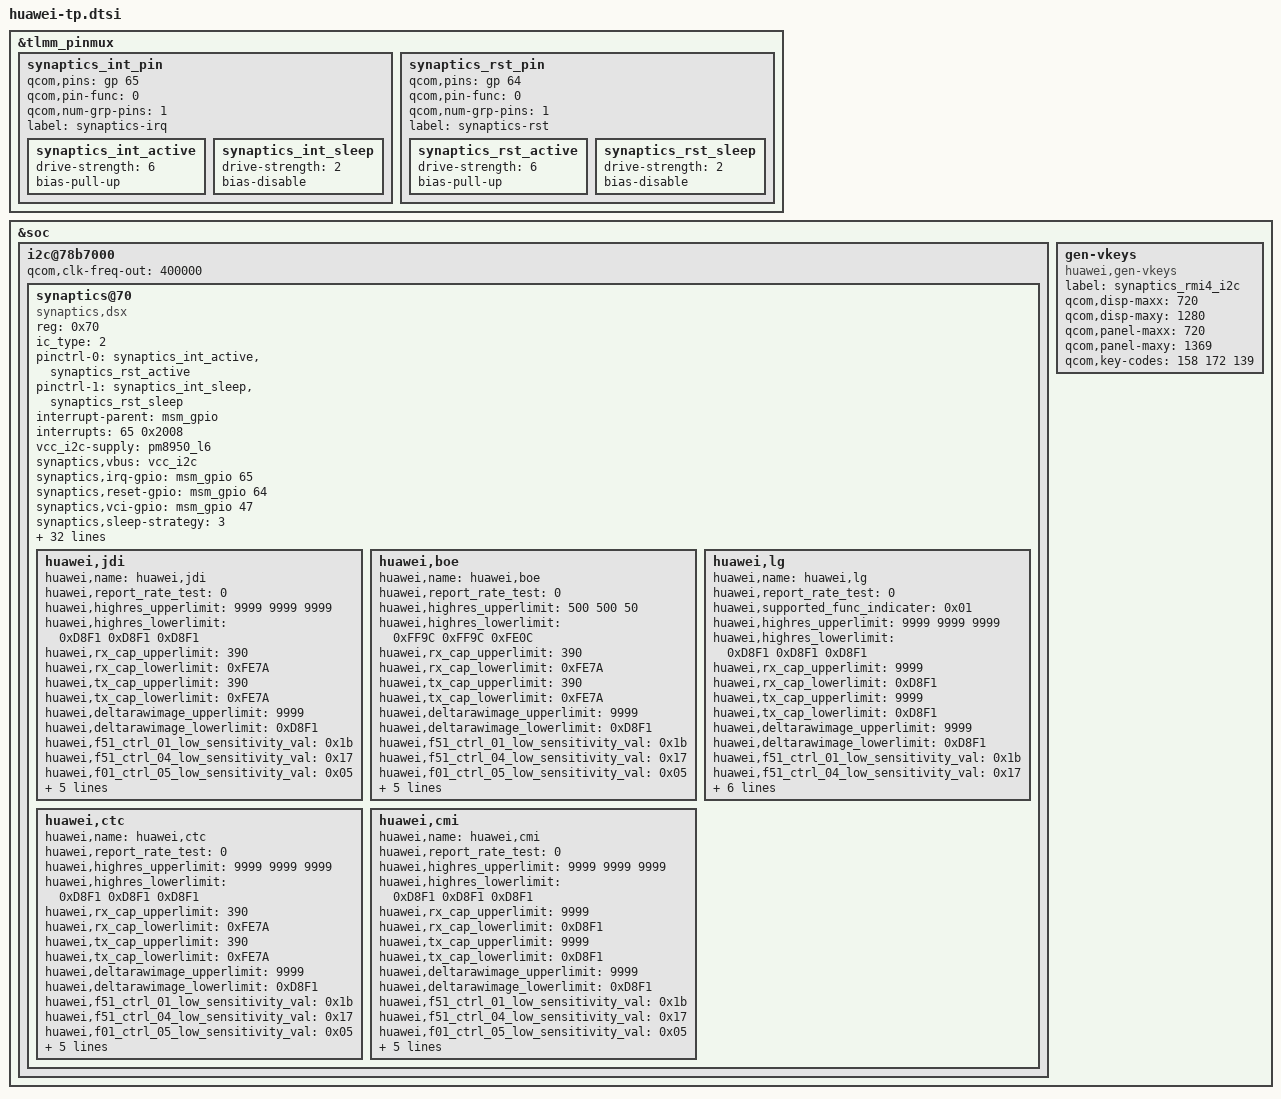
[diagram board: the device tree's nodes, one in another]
/* Modify JDI tp/lcd power on/off to reduce power consumption */
/* Modify JDI tp reset gpio pinctrl for power consumption */
/*Ath TP not working in glove mode*/
/* move l16 control to ATH device config file */
&tlmm_pinmux {

	synaptics_int_pin {
		qcom,pins = <&gp 65>;
		qcom,pin-func = <0>;
		qcom,num-grp-pins = <1>;
		label = "synaptics-irq";
		synaptics_int_active: synaptics_int_active {
			drive-strength = <6>;
			bias-pull-up;
		};
		synaptics_int_sleep: synaptics_int_sleep {
			drive-strength = <2>;
			bias-disable;
		};
	};

	synaptics_rst_pin {
		qcom,pins = <&gp 64>;
		qcom,pin-func = <0>;
		qcom,num-grp-pins = <1>;
		label = "synaptics-rst";
		synaptics_rst_active: synaptics_rst_active {
			drive-strength = <6>;
			bias-pull-up;
		};
		synaptics_rst_sleep: synaptics_rst_sleep {
			drive-strength = <2>;
			bias-disable;
		};
	};
};

&soc {
    i2c@78b7000 { /* BLSP1 QUP5 */
		status = "ok";
		#address-cells = <1>;
		#size-cells = <0>;
		qcom,clk-freq-out = <400000>;
		synaptics@70 {
			compatible = "synaptics,dsx";
			reg = <0x70>;

			/* SYNAPTICS_S3207 = 0 */
			/* SYNAPTICS_S3350 = 1 */
			/* SYNAPTICS_S3320 = 2 */
			/* SYNAPTICS_S3718 = 3 */
			ic_type = <2>;

			pinctrl-names = "active","sleep";
			pinctrl-0 = <&synaptics_int_active &synaptics_rst_active>;
			pinctrl-1 = <&synaptics_int_sleep &synaptics_rst_sleep>;

			interrupt-parent = <&msm_gpio>;
			interrupts = <65 0x2008>;
			//vdd-supply = <&pm8950_l17>;
			vcc_i2c-supply = <&pm8950_l6>;
			/* Some of qcom's param will not be replaced by huawei in dtb, */
			/* just ignore them:such as "pinctrl-names","pinctrl-0","pinctrl-1", */
			/* "synaptics,display-coords","synaptics,panel-coords","synaptics,i2c-pull-up", */
			/* "synaptics,power-down","synaptics,disable-gpios"*/
			//synaptics,vdd = "vdd";
			synaptics,vbus = "vcc_i2c";
			synaptics,irq-gpio = <&msm_gpio 65 0x2008>;
			synaptics,reset-gpio = <&msm_gpio 64 0x0>;
			synaptics,vci-gpio = <&msm_gpio 47 0x0>;

			/* synaptics,sleep/wake strategy */

			/* SLEEP_STRATEGY_DEEP_SLEEP    : 0*/
			/* SLEEP_STRATEGY_POWER_DOWN    : 1*/
			/* SLEEP_STRATEGY_KEEP_WAKE     : 2*/
			/* SLEEP_STRATEGY_ALWAYS_RESET  : 3*/
			synaptics,sleep-strategy = <3>;

			synaptics,lcd-x = <1080>;
			synaptics,lcd-y = <1920>;
			synaptics,lcd-all = <1920>;
			synaptics,virtual_keys = /* KeyCode CenterX CenterY Width Height */
				/* KEY_BACK */
				<158 142 1342 150 100
				/* KEY_HOME(172) */
				172 360 1342 150 100
				/* KEY_MENU */
				139 578 1342 150 100>;

			/* SYNAPTICS_WAKE_UP_GESTURE_FLAG:'1'->enabled,'0'->disabled */
			/*IC flash is not enough for holster,so fw del one gesture*/
			synaptics,gesture_enabled = <0>;
			/* Gestures that supported:                           */
			/* bit0  Double tap                                        */
			/* bit1  Single finger slide from left to right     */
			/* bit2  Single finger slide from right to left     */
			/* bit3  Single finger slide from top to bottom  */
			/* bit4  Single finger slide from bottom to top  */
			/* bit5  Double finger slide from top to bottom--disable for holster*/
			/* bit6  Single finger slide circle                     */
			/* bit7  Single finger write letter c                  */
			/* bit8  Single finger write letter e                  */
			/* bit9  Single finger write letter m                 */
			/* bit10 Single finger write letter w                 */
			/* bit11 Palm off screen                                */
			synaptics,easy_wakeup_supported_gestures = <0xF81>;

			/*Defination of report key value  for different gestures*/
			synaptics,easy_wakeup_gesture_keys = 
			<	59 /*0.Double tap:                                  KEY_F1*/
				60 /*1.Single finger slide from left to right:      KEY_F2*/
				61 /*2.Single finger slide from right to left:      KEY_F3*/
				62 /*3.Single finger slide from top to bottom:      KEY_F4*/
				63 /*4.Single finger slide from bottom to top:      KEY_F5*/
				64 /*5.Single finger slide circle clockwise:        KEY_F6*/
				65 /*6.Single finger slide circle counter-clockwise:KEY_F7*/
				66 /*7.Single finger write letter c:                KEY_F8*/
				67 /*8.Single finger write letter e:                KEY_F9*/
				68 /*9.Single finger write letter m:                KEY_F10*/
				87 /*10.Single finger write letter w:               KEY_F11*/
				88 /*11.Palm off screen:                            KEY_F12*/
			>;

			/* Double-tap-zone defined by huawei */
			/* Shielded area is:1cm left,1cm right,3cm up,2cm down */
			huawei,dtz_x0 = <1>;
			huawei,dtz_y0 = <1>;
			huawei,dtz_x1 = <1080>;
			huawei,dtz_y1 = <1920>;

			/* GLOVE FLAG default state:'1'->enabled,'0'->disabled*/
			synaptics,glove_enabled = <0>;
			/*After reduce power-consumption by exit reduce mode,*/
			/*we have to reduce f-r rate to make sure gesture work fine*/
			synaptics,fast_relax_gesture = <0>;
			/*Holster support flag*/
			synaptics,holster_supported = <0>;
			synaptics,glove_edge_switch_supported = <0>;
			synaptics,grip_algorithm_supported = <0>;
			synaptics,grip_algorithm_enabled = <0>;
			huawei,grip_left_lsb = <0x32>;
			huawei,grip_left_msb = <0x0>;
			huawei,grip_right_lsb = <0x1A>;
			huawei,grip_right_msb = <0x04>;

			/*dwt represent doze wakeup threshold in gesture mode*/
			synaptics,ofilm_dwt = <30>;
			synaptics,truly_dwt = <30>;
			synaptics,junda_dwt = <30>;

			synaptics,reset-on-status = <0>;
			synaptics,power-delay-ms = <160>;
			synaptics,reset-delay-ms = <200>;
			synaptics,reset-active-ms = <10>;
			synaptics,product_name = "venus";

			/*capacitance self-adapt*/
			huawei,jdi {
				huawei,name = "huawei,jdi";
				huawei,report_rate_test = <0>; /* 0:disable test, 1:enable test */

				huawei,highres_upperlimit = <9999 9999 9999>;
				huawei,highres_lowerlimit = <0xD8F1 0xD8F1 0xD8F1>;/* 0xD8F1 == -9999 */

				huawei,rx_cap_upperlimit = <390>;
				huawei,rx_cap_lowerlimit = <0xFE7A>;

				huawei,tx_cap_upperlimit = <390>;
				huawei,tx_cap_lowerlimit = <0xFE7A>;

				huawei,deltarawimage_upperlimit = <9999>;
				huawei,deltarawimage_lowerlimit = <0xD8F1>;

				huawei,f51_ctrl_01_low_sensitivity_val = <0x1b>;
				huawei,f51_ctrl_04_low_sensitivity_val = <0x17>;
				huawei,f01_ctrl_05_low_sensitivity_val = <0x05>;
				huawei,f01_ctrl_09_low_sensitivity_val = <0x04>;

				huawei,fullraw_upperlimit =
					<2550 2550 2550 2550 2550 2550 2550 2550 2550 2550 2550 2550 2550 2550 2550 2550
					2550 2550 2550 2550 2550 2550 2550 2550 2550 2550 2550 2550 2550 2550 2550 2550
					2550 2550 2550 2550 2550 2550 2550 2550 2550 2550 2550 2550 2550 2550 2550 2550
					2550 2550 2550 2550 2550 2550 2550 2550 2550 2550 2550 2550 2550 2550 2550 2550
					2550 2550 2550 2550 2550 2550 2550 2550 2550 2550 2550 2550 2550 2550 2550 2550
					2550 2550 2550 2550 2550 2550 2550 2550 2550 2550 2550 2550 2550 2550 2550 2550
					2550 2550 2550 2550 2550 2550 2550 2550 2550 2550 2550 2550 2550 2550 2550 2550
					2550 2550 2550 2550 2550 2550 2550 2550 2550 2550 2550 2550 2550 2550 2550 2550
					2550 2550 2550 2550 2550 2550 2550 2550 2550 2550 2550 2550 2550 2550 2550 2550
					2550 2550 2550 2550 2550 2550 2550 2550 2550 2550 2550 2550 2550 2550 2550 2550
					2550 2550 2550 2550 2550 2550 2550 2550 2550 2550 2550 2550 2550 2550 2550 2550
					2550 2550 2550 2550 2550 2550 2550 2550 2550 2550 2550 2550 2550 2550 2550 2550
					2550 2550 2550 2550 2550 2550 2550 2550 2550 2550 2550 2550 2550 2550 2550 2550
					2550 2550 2550 2550 2550 2550 2550 2550 2550 2550 2550 2550 2550 2550 2550 2550
					2550 2550 2550 2550 2550 2550 2550 2550 2550 2550 2550 2550 2550 2550 2550 2550
					2550 2550 2550 2550 2550 2550 2550 2550 2550 2550 2550 2550 2550 2550 2550 2550
					2550 2550 2550 2550 2550 2550 2550 2550 2550 2550 2550 2550 2550 2550 2550 2550
					2550 2550 2550 2550 2550 2550 2550 2550 2550 2550 2550 2550 2550 2550 2550 2550
					2550 2550 2550 2550 2550 2550 2550 2550 2550 2550 2550 2550 2550 2550 2550 2550
					2550 2550 2550 2550 2550 2550 2550 2550 2550 2550 2550 2550 2550 2550 2550 2550
					2550 2550 2550 2550 2550 2550 2550 2550 2550 2550 2550 2550 2550 2550 2550 2550
					2550 2550 2550 2550 2550 2550 2550 2550 2550 2550 2550 2550 2550 2550 2550 2550
					2550 2550 2550 2550 2550 2550 2550 2550 2550 2550 2550 2550 2550 2550 2550 2550
					2550 2550 2550 2550 2550 2550 2550 2550 2550 2550 2550 2550 2550 2550 2550 2550
					2550 2550 2550 2550 2550 2550 2550 2550 2550 2550 2550 2550 2550 2550 2550 2550
					2550 2550 2550 2550 2550 2550 2550 2550 2550 2550 2550 2550 2550 2550 2550 2550
					2550 2550 2550 2550 2550 2550 2550 2550 2550 2550 2550 2550 2550 2550 2550 2550
					2550 2550 2550 2550 2550 2550 2550 2550 2550 2550 2550 2550 2550 2550 2550 2550>;

				huawei,fullraw_lowerlimit =
					<1500 1500 1500 1500 1500 1500 1500 1500 1500 1500 1500 1500 1500 1500 1500 1500
					1500 1500 1500 1500 1500 1500 1500 1500 1500 1500 1500 1500 1500 1500 1500 1500
					1500 1500 1500 1500 1500 1500 1500 1500 1500 1500 1500 1500 1500 1500 1500 1500
					1500 1500 1500 1500 1500 1500 1500 1500 1500 1500 1500 1500 1500 1500 1500 1500
					1500 1500 1500 1500 1500 1500 1500 1500 1500 1500 1500 1500 1500 1500 1500 1500
					1500 1500 1500 1500 1500 1500 1500 1500 1500 1500 1500 1500 1500 1500 1500 1500
					1500 1500 1500 1500 1500 1500 1500 1500 1500 1500 1500 1500 1500 1500 1500 1500
					1500 1500 1500 1500 1500 1500 1500 1500 1500 1500 1500 1500 1500 1500 1500 1500
					1500 1500 1500 1500 1500 1500 1500 1500 1500 1500 1500 1500 1500 1500 1500 1500
					1500 1500 1500 1500 1500 1500 1500 1500 1500 1500 1500 1500 1500 1500 1500 1500
					1500 1500 1500 1500 1500 1500 1500 1500 1500 1500 1500 1500 1500 1500 1500 1500
					1500 1500 1500 1500 1500 1500 1500 1500 1500 1500 1500 1500 1500 1500 1500 1500
					1500 1500 1500 1500 1500 1500 1500 1500 1500 1500 1500 1500 1500 1500 1500 1500
					1500 1500 1500 1500 1500 1500 1500 1500 1500 1500 1500 1500 1500 1500 1500 1500
					1500 1500 1500 1500 1500 1500 1500 1500 1500 1500 1500 1500 1500 1500 1500 1500
					1500 1500 1500 1500 1500 1500 1500 1500 1500 1500 1500 1500 1500 1500 1500 1500
					1500 1500 1500 1500 1500 1500 1500 1500 1500 1500 1500 1500 1500 1500 1500 1500
					1500 1500 1500 1500 1500 1500 1500 1500 1500 1500 1500 1500 1500 1500 1500 1500
					1500 1500 1500 1500 1500 1500 1500 1500 1500 1500 1500 1500 1500 1500 1500 1500
					1500 1500 1500 1500 1500 1500 1500 1500 1500 1500 1500 1500 1500 1500 1500 1500
					1500 1500 1500 1500 1500 1500 1500 1500 1500 1500 1500 1500 1500 1500 1500 1500
					1500 1500 1500 1500 1500 1500 1500 1500 1500 1500 1500 1500 1500 1500 1500 1500
					1500 1500 1500 1500 1500 1500 1500 1500 1500 1500 1500 1500 1500 1500 1500 1500
					1500 1500 1500 1500 1500 1500 1500 1500 1500 1500 1500 1500 1500 1500 1500 1500
					1500 1500 1500 1500 1500 1500 1500 1500 1500 1500 1500 1500 1500 1500 1500 1500
					1500 1500 1500 1500 1500 1500 1500 1500 1500 1500 1500 1500 1500 1500 1500 1500
					1500 1500 1500 1500 1500 1500 1500 1500 1500 1500 1500 1500 1500 1500 1500 1500
					1500 1500 1500 1500 1500 1500 1500 1500 1500 1500 1500 1500 1500 1500 1500 1500>;
			};

			huawei,boe {
				huawei,name = "huawei,boe";
				huawei,report_rate_test = <0>; /* 0:disable test, 1:enable test */

				huawei,highres_upperlimit = <500 500 50>;
				huawei,highres_lowerlimit = <0xFF9C 0xFF9C 0xFE0C>;/* 0xD8F1 == -9999 */

				huawei,rx_cap_upperlimit = <390>;
				huawei,rx_cap_lowerlimit = <0xFE7A>;

				huawei,tx_cap_upperlimit = <390>;
				huawei,tx_cap_lowerlimit = <0xFE7A>;

				huawei,deltarawimage_upperlimit = <9999>;
				huawei,deltarawimage_lowerlimit = <0xD8F1>;

				huawei,f51_ctrl_01_low_sensitivity_val = <0x1b>;
				huawei,f51_ctrl_04_low_sensitivity_val = <0x17>;
				huawei,f01_ctrl_05_low_sensitivity_val = <0x05>;
				huawei,f01_ctrl_09_low_sensitivity_val = <0x04>;

				huawei,fullraw_upperlimit =
					<3394 3354 3291 3253 3117 3109 3105 3103 3089 3100 3092 3104 3243 3288 3358 3434
					3534 3515 3455 3416 3276 3269 3264 3263 3250 3261 3254 3267 3405 3450 3519 3560
					3557 3543 3482 3444 3304 3296 3292 3290 3277 3289 3283 3295 3433 3478 3547 3583
					3573 3561 3502 3465 3325 3318 3313 3311 3299 3310 3304 3315 3454 3497 3566 3599
					3588 3579 3520 3485 3345 3337 3333 3331 3319 3331 3324 3336 3474 3516 3582 3614
					3596 3589 3531 3496 3357 3349 3344 3343 3330 3341 3335 3346 3484 3526 3591 3622
					3605 3598 3541 3506 3368 3360 3356 3353 3340 3352 3345 3356 3494 3535 3600 3630
					3609 3603 3546 3511 3372 3365 3366 3357 3344 3355 3349 3360 3497 3539 3604 3633
					3613 3606 3550 3515 3376 3369 3364 3362 3349 3359 3353 3364 3502 3544 3608 3637
					3611 3605 3549 3514 3374 3367 3363 3360 3347 3358 3352 3363 3501 3542 3606 3635
					3613 3607 3550 3516 3376 3368 3364 3361 3348 3358 3353 3364 3501 3543 3607 3636
					3610 3603 3546 3512 3372 3364 3359 3358 3346 3356 3350 3361 3498 3538 3603 3631
					3610 3603 3546 3512 3373 3365 3361 3358 3346 3356 3350 3361 3496 3538 3602 3631
					3605 3598 3541 3507 3367 3361 3356 3353 3341 3351 3346 3356 3492 3533 3597 3626
					3599 3591 3534 3501 3361 3354 3350 3347 3335 3346 3341 3350 3486 3526 3590 3619
					3586 3579 3523 3490 3350 3343 3338 3336 3324 3335 3329 3338 3475 3515 3578 3609
					3577 3569 3513 3480 3341 3334 3329 3329 3317 3327 3321 3330 3465 3506 3568 3598
					3563 3555 3499 3466 3328 3321 3317 3317 3304 3315 3308 3316 3452 3492 3554 3583
					3547 3538 3483 3449 3310 3304 3300 3300 3288 3298 3291 3300 3435 3474 3536 3567
					3538 3530 3474 3441 3302 3296 3292 3292 3279 3289 3283 3292 3427 3466 3528 3557
					3524 3517 3460 3427 3289 3283 3278 3278 3265 3276 3269 3279 3413 3453 3514 3544
					3510 3501 3446 3413 3274 3267 3262 3262 3250 3260 3253 3263 3398 3437 3499 3529
					3497 3489 3432 3399 3263 3254 3250 3249 3238 3247 3239 3249 3384 3423 3485 3515
					3481 3473 3415 3382 3243 3238 3235 3234 3223 3231 3223 3232 3367 3407 3469 3498
					3469 3460 3403 3369 3230 3225 3221 3222 3210 3219 3210 3218 3353 3393 3457 3488
					3454 3444 3385 3351 3212 3207 3205 3205 3194 3204 3193 3201 3336 3378 3441 3475
					3439 3426 3369 3334 3195 3189 3187 3189 3178 3187 3176 3184 3320 3362 3425 3461
					3331 3303 3244 3208 3071 3062 3063 3062 3051 3065 3054 3062 3201 3242 3305 3356>;

				huawei,fullraw_lowerlimit =
					<1779 1754 1719 1708 1644 1646 1646 1636 1634 1631 1634 1635 1708 1728 1767 1800
					1848 1835 1801 1789 1724 1724 1725 1714 1714 1710 1715 1716 1792 1809 1850 1869
					1857 1845 1810 1797 1733 1734 1735 1724 1725 1722 1726 1733 1803 1821 1860 1878
					1867 1854 1818 1806 1741 1742 1744 1733 1735 1732 1736 1740 1813 1830 1870 1889
					1876 1864 1828 1817 1750 1751 1751 1742 1744 1741 1744 1745 1821 1839 1880 1897
					1881 1868 1833 1824 1757 1757 1757 1747 1751 1747 1750 1750 1826 1845 1887 1903
					1887 1873 1838 1831 1764 1763 1764 1755 1758 1755 1757 1758 1834 1853 1894 1910
					1885 1872 1838 1828 1762 1761 1764 1755 1758 1755 1758 1760 1835 1854 1896 1913
					1885 1872 1838 1828 1761 1762 1763 1751 1756 1754 1758 1758 1835 1854 1897 1912
					1887 1873 1840 1830 1763 1764 1764 1755 1758 1755 1760 1761 1837 1856 1897 1913
					1884 1870 1837 1828 1760 1760 1762 1752 1755 1753 1757 1759 1834 1853 1894 1910
					1881 1868 1835 1826 1758 1758 1759 1749 1751 1749 1754 1758 1834 1851 1893 1908
					1880 1866 1834 1823 1754 1755 1757 1746 1749 1746 1750 1754 1829 1849 1890 1906
					1874 1860 1828 1818 1756 1750 1753 1744 1744 1742 1747 1749 1825 1844 1885 1902
					1871 1856 1823 1815 1747 1747 1748 1738 1740 1737 1742 1744 1820 1839 1881 1896
					1865 1852 1820 1810 1743 1742 1744 1737 1737 1734 1738 1738 1815 1833 1875 1891
					1862 1848 1816 1808 1739 1738 1739 1737 1734 1730 1732 1734 1809 1829 1869 1885
					1853 1838 1806 1799 1730 1730 1730 1723 1725 1721 1723 1724 1801 1819 1860 1877
					1840 1826 1793 1786 1716 1717 1718 1711 1712 1708 1712 1714 1790 1808 1849 1866
					1836 1820 1787 1777 1709 1710 1711 1702 1704 1702 1706 1708 1784 1801 1842 1858
					1828 1810 1778 1769 1699 1699 1701 1693 1696 1694 1698 1699 1775 1794 1833 1850
					1817 1802 1768 1760 1690 1690 1693 1684 1686 1685 1689 1690 1766 1784 1823 1841
					1812 1797 1762 1754 1685 1685 1686 1680 1681 1677 1681 1683 1759 1778 1818 1836
					1801 1788 1756 1745 1676 1675 1678 1670 1672 1668 1670 1673 1750 1767 1808 1826
					1794 1781 1747 1737 1668 1668 1669 1661 1663 1659 1662 1664 1740 1757 1798 1815
					1786 1771 1744 1728 1660 1660 1661 1654 1654 1649 1653 1655 1732 1747 1787 1806
					1782 1767 1735 1726 1655 1655 1657 1649 1650 1644 1647 1649 1724 1740 1778 1795
					1716 1696 1662 1654 1583 1583 1583 1577 1578 1570 1571 1570 1647 1664 1702 1729>;
			};

			huawei,lg {
				huawei,name = "huawei,lg";
				huawei,report_rate_test = <0>; /* 0:disable test, 1:enable test */
				huawei,supported_func_indicater = <0x01>;


				huawei,highres_upperlimit = <9999 9999 9999>;
				huawei,highres_lowerlimit = <0xD8F1 0xD8F1 0xD8F1>;/* 0xD8F1 == -9999 */

				huawei,rx_cap_upperlimit = <9999>;
				huawei,rx_cap_lowerlimit = <0xD8F1>;

				huawei,tx_cap_upperlimit = <9999>;
				huawei,tx_cap_lowerlimit = <0xD8F1>;

				huawei,deltarawimage_upperlimit = <9999>;
				huawei,deltarawimage_lowerlimit = <0xD8F1>;

				huawei,f51_ctrl_01_low_sensitivity_val = <0x1b>;
				huawei,f51_ctrl_04_low_sensitivity_val = <0x17>;
				huawei,f01_ctrl_05_low_sensitivity_val = <0x05>;
				huawei,f01_ctrl_09_low_sensitivity_val = <0x04>;

				huawei,fullraw_upperlimit =
					<9999 9999 9999 9999 9999 9999 9999 9999 9999 9999 9999 9999 9999 9999 9999 9999 9999 9999 9999 9999 9999 9999 9999 9999 9999 9999 9999 9999
					9999 9999 9999 9999 9999 9999 9999 9999 9999 9999 9999 9999 9999 9999 9999 9999 9999 9999 9999 9999 9999 9999 9999 9999 9999 9999 9999 9999
					9999 9999 9999 9999 9999 9999 9999 9999 9999 9999 9999 9999 9999 9999 9999 9999 9999 9999 9999 9999 9999 9999 9999 9999 9999 9999 9999 9999
					9999 9999 9999 9999 9999 9999 9999 9999 9999 9999 9999 9999 9999 9999 9999 9999 9999 9999 9999 9999 9999 9999 9999 9999 9999 9999 9999 9999
					9999 9999 9999 9999 9999 9999 9999 9999 9999 9999 9999 9999 9999 9999 9999 9999 9999 9999 9999 9999 9999 9999 9999 9999 9999 9999 9999 9999
					9999 9999 9999 9999 9999 9999 9999 9999 9999 9999 9999 9999 9999 9999 9999 9999 9999 9999 9999 9999 9999 9999 9999 9999 9999 9999 9999 9999
					9999 9999 9999 9999 9999 9999 9999 9999 9999 9999 9999 9999 9999 9999 9999 9999 9999 9999 9999 9999 9999 9999 9999 9999 9999 9999 9999 9999
					9999 9999 9999 9999 9999 9999 9999 9999 9999 9999 9999 9999 9999 9999 9999 9999 9999 9999 9999 9999 9999 9999 9999 9999 9999 9999 9999 9999
					9999 9999 9999 9999 9999 9999 9999 9999 9999 9999 9999 9999 9999 9999 9999 9999 9999 9999 9999 9999 9999 9999 9999 9999 9999 9999 9999 9999
					9999 9999 9999 9999 9999 9999 9999 9999 9999 9999 9999 9999 9999 9999 9999 9999 9999 9999 9999 9999 9999 9999 9999 9999 9999 9999 9999 9999
					9999 9999 9999 9999 9999 9999 9999 9999 9999 9999 9999 9999 9999 9999 9999 9999 9999 9999 9999 9999 9999 9999 9999 9999 9999 9999 9999 9999
					9999 9999 9999 9999 9999 9999 9999 9999 9999 9999 9999 9999 9999 9999 9999 9999 9999 9999 9999 9999 9999 9999 9999 9999 9999 9999 9999 9999
					9999 9999 9999 9999 9999 9999 9999 9999 9999 9999 9999 9999 9999 9999 9999 9999 9999 9999 9999 9999 9999 9999 9999 9999 9999 9999 9999 9999
					9999 9999 9999 9999 9999 9999 9999 9999 9999 9999 9999 9999 9999 9999 9999 9999 9999 9999 9999 9999 9999 9999 9999 9999 9999 9999 9999 9999
					9999 9999 9999 9999 9999 9999 9999 9999 9999 9999 9999 9999 9999 9999 9999 9999 9999 9999 9999 9999 9999 9999 9999 9999 9999 9999 9999 9999
					9999 9999 9999 9999 9999 9999 9999 9999 9999 9999 9999 9999 9999 9999 9999 9999 9999 9999 9999 9999 9999 9999 9999 9999 9999 9999 9999 9999>;

				huawei,fullraw_lowerlimit =
					<0 0 0 0 0 0 0 0 0 0 0 0 0 0 0 0 0 0 0 0 0 0 0 0 0 0 0 0
					0 0 0 0 0 0 0 0 0 0 0 0 0 0 0 0 0 0 0 0 0 0 0 0 0 0 0 0
					0 0 0 0 0 0 0 0 0 0 0 0 0 0 0 0 0 0 0 0 0 0 0 0 0 0 0 0
					0 0 0 0 0 0 0 0 0 0 0 0 0 0 0 0 0 0 0 0 0 0 0 0 0 0 0 0
					0 0 0 0 0 0 0 0 0 0 0 0 0 0 0 0 0 0 0 0 0 0 0 0 0 0 0 0
					0 0 0 0 0 0 0 0 0 0 0 0 0 0 0 0 0 0 0 0 0 0 0 0 0 0 0 0
					0 0 0 0 0 0 0 0 0 0 0 0 0 0 0 0 0 0 0 0 0 0 0 0 0 0 0 0
					0 0 0 0 0 0 0 0 0 0 0 0 0 0 0 0 0 0 0 0 0 0 0 0 0 0 0 0
					0 0 0 0 0 0 0 0 0 0 0 0 0 0 0 0 0 0 0 0 0 0 0 0 0 0 0 0
					0 0 0 0 0 0 0 0 0 0 0 0 0 0 0 0 0 0 0 0 0 0 0 0 0 0 0 0
					0 0 0 0 0 0 0 0 0 0 0 0 0 0 0 0 0 0 0 0 0 0 0 0 0 0 0 0
					0 0 0 0 0 0 0 0 0 0 0 0 0 0 0 0 0 0 0 0 0 0 0 0 0 0 0 0
					0 0 0 0 0 0 0 0 0 0 0 0 0 0 0 0 0 0 0 0 0 0 0 0 0 0 0 0
					0 0 0 0 0 0 0 0 0 0 0 0 0 0 0 0 0 0 0 0 0 0 0 0 0 0 0 0
					0 0 0 0 0 0 0 0 0 0 0 0 0 0 0 0 0 0 0 0 0 0 0 0 0 0 0 0
					0 0 0 0 0 0 0 0 0 0 0 0 0 0 0 0 0 0 0 0 0 0 0 0 0 0 0 0>;
			};

			huawei,ctc {
				huawei,name = "huawei,ctc";
				huawei,report_rate_test = <0>; /* 0:disable test, 1:enable test */

				huawei,highres_upperlimit = <9999 9999 9999>;
				huawei,highres_lowerlimit = <0xD8F1 0xD8F1 0xD8F1>;/* 0xD8F1 == -9999 */

				huawei,rx_cap_upperlimit = <390>;
				huawei,rx_cap_lowerlimit = <0xFE7A>;

				huawei,tx_cap_upperlimit = <390>;
				huawei,tx_cap_lowerlimit = <0xFE7A>;

				huawei,deltarawimage_upperlimit = <9999>;
				huawei,deltarawimage_lowerlimit = <0xD8F1>;

				huawei,f51_ctrl_01_low_sensitivity_val = <0x1b>;
				huawei,f51_ctrl_04_low_sensitivity_val = <0x17>;
				huawei,f01_ctrl_05_low_sensitivity_val = <0x05>;
				huawei,f01_ctrl_09_low_sensitivity_val = <0x04>;

				huawei,fullraw_upperlimit =
					<2600 2600 2600 2600 2600 2600 2600 2600 2600 2600 2600 2600 2600 2600 2600 2600 2600
					2600 2600 2600 2600 2600 2600 2600 2600 2600 2600 2600 2600 2600 2600 2600 2600 2600
					2600 2600 2600 2600 2600 2600 2600 2600 2600 2600 2600 2600 2600 2600 2600 2600 2600
					2600 2600 2600 2600 2600 2600 2600 2600 2600 2600 2600 2600 2600 2600 2600 2600 2600
					2600 2600 2600 2600 2600 2600 2600 2600 2600 2600 2600 2600 2600 2600 2600 2600 2600
					2600 2600 2600 2600 2600 2600 2600 2600 2600 2600 2600 2600 2600 2600 2600 2600 2600
					2600 2600 2600 2600 2600 2600 2600 2600 2600 2600 2600 2600 2600 2600 2600 2600 2600
					2600 2600 2600 2600 2600 2600 2600 2600 2600 2600 2600 2600 2600 2600 2600 2600 2600
					2600 2600 2600 2600 2600 2600 2600 2600 2600 2600 2600 2600 2600 2600 2600 2600 2600
					2600 2600 2600 2600 2600 2600 2600 2600 2600 2600 2600 2600 2600 2600 2600 2600 2600
					2600 2600 2600 2600 2600 2600 2600 2600 2600 2600 2600 2600 2600 2600 2600 2600 2600
					2600 2600 2600 2600 2600 2600 2600 2600 2600 2600 2600 2600 2600 2600 2600 2600 2600
					2600 2600 2600 2600 2600 2600 2600 2600 2600 2600 2600 2600 2600 2600 2600 2600 2600
					2600 2600 2600 2600 2600 2600 2600 2600 2600 2600 2600 2600 2600 2600 2600 2600 2600
					2600 2600 2600 2600 2600 2600 2600 2600 2600 2600 2600 2600 2600 2600 2600 2600 2600
					2600 2600 2600 2600 2600 2600 2600 2600 2600 2600 2600 2600 2600 2600 2600 2600 2600
					2600 2600 2600 2600 2600 2600 2600 2600 2600 2600 2600 2600 2600 2600 2600 2600 2600
					2600 2600 2600 2600 2600 2600 2600 2600 2600 2600 2600 2600 2600 2600 2600 2600 2600
					2600 2600 2600 2600 2600 2600 2600 2600 2600 2600 2600 2600 2600 2600 2600 2600 2600
					2600 2600 2600 2600 2600 2600 2600 2600 2600 2600 2600 2600 2600 2600 2600 2600 2600
					2600 2600 2600 2600 2600 2600 2600 2600 2600 2600 2600 2600 2600 2600 2600 2600 2600
					2600 2600 2600 2600 2600 2600 2600 2600 2600 2600 2600 2600 2600 2600 2600 2600 2600
					2600 2600 2600 2600 2600 2600 2600 2600 2600 2600 2600 2600 2600 2600 2600 2600 2600
					2600 2600 2600 2600 2600 2600 2600 2600 2600 2600 2600 2600 2600 2600 2600 2600 2600
					2600 2600 2600 2600 2600 2600 2600 2600 2600 2600 2600 2600 2600 2600 2600 2600 2600
					2600 2600 2600 2600 2600 2600 2600 2600 2600 2600 2600 2600 2600 2600 2600 2600 2600
					2600 2600 2600 2600 2600 2600 2600 2600 2600 2600 2600 2600 2600 2600 2600 2600 2600
					2600 2600 2600 2600 2600 2600 2600 2600 2600 2600 2600 2600 2600 2600 2600 2600 2600
					2600 2600 2600 2600 2600 2600 2600 2600 2600 2600 2600 2600 2600 2600 2600 2600 2600
					2600 2600 2600 2600 2600 2600 2600 2600 2600 2600 2600 2600 2600 2600 2600 2600 2600>;

				huawei,fullraw_lowerlimit =
					<1750 1750 1750 1750 1750 1750 1750 1750 1750 1750 1750 1750 1750 1750 1750 1750 1750
					1750 1750 1750 1750 1750 1750 1750 1750 1750 1750 1750 1750 1750 1750 1750 1750 1750
					1750 1750 1750 1750 1750 1750 1750 1750 1750 1750 1750 1750 1750 1750 1750 1750 1750
					1750 1750 1750 1750 1750 1750 1750 1750 1750 1750 1750 1750 1750 1750 1750 1750 1750
					1750 1750 1750 1750 1750 1750 1750 1750 1750 1750 1750 1750 1750 1750 1750 1750 1750
					1750 1750 1750 1750 1750 1750 1750 1750 1750 1750 1750 1750 1750 1750 1750 1750 1750
					1750 1750 1750 1750 1750 1750 1750 1750 1750 1750 1750 1750 1750 1750 1750 1750 1750
					1750 1750 1750 1750 1750 1750 1750 1750 1750 1750 1750 1750 1750 1750 1750 1750 1750
					1750 1750 1750 1750 1750 1750 1750 1750 1750 1750 1750 1750 1750 1750 1750 1750 1750
					1750 1750 1750 1750 1750 1750 1750 1750 1750 1750 1750 1750 1750 1750 1750 1750 1750
					1750 1750 1750 1750 1750 1750 1750 1750 1750 1750 1750 1750 1750 1750 1750 1750 1750
					1750 1750 1750 1750 1750 1750 1750 1750 1750 1750 1750 1750 1750 1750 1750 1750 1750
					1750 1750 1750 1750 1750 1750 1750 1750 1750 1750 1750 1750 1750 1750 1750 1750 1750
					1750 1750 1750 1750 1750 1750 1750 1750 1750 1750 1750 1750 1750 1750 1750 1750 1750
					1750 1750 1750 1750 1750 1750 1750 1750 1750 1750 1750 1750 1750 1750 1750 1750 1750
					1750 1750 1750 1750 1750 1750 1750 1750 1750 1750 1750 1750 1750 1750 1750 1750 1750
					1750 1750 1750 1750 1750 1750 1750 1750 1750 1750 1750 1750 1750 1750 1750 1750 1750
					1750 1750 1750 1750 1750 1750 1750 1750 1750 1750 1750 1750 1750 1750 1750 1750 1750
					1750 1750 1750 1750 1750 1750 1750 1750 1750 1750 1750 1750 1750 1750 1750 1750 1750
					1750 1750 1750 1750 1750 1750 1750 1750 1750 1750 1750 1750 1750 1750 1750 1750 1750
					1750 1750 1750 1750 1750 1750 1750 1750 1750 1750 1750 1750 1750 1750 1750 1750 1750
					1750 1750 1750 1750 1750 1750 1750 1750 1750 1750 1750 1750 1750 1750 1750 1750 1750
					1750 1750 1750 1750 1750 1750 1750 1750 1750 1750 1750 1750 1750 1750 1750 1750 1750
					1750 1750 1750 1750 1750 1750 1750 1750 1750 1750 1750 1750 1750 1750 1750 1750 1750
					1750 1750 1750 1750 1750 1750 1750 1750 1750 1750 1750 1750 1750 1750 1750 1750 1750
					1750 1750 1750 1750 1750 1750 1750 1750 1750 1750 1750 1750 1750 1750 1750 1750 1750
					1750 1750 1750 1750 1750 1750 1750 1750 1750 1750 1750 1750 1750 1750 1750 1750 1750
					1750 1750 1750 1750 1750 1750 1750 1750 1750 1750 1750 1750 1750 1750 1750 1750 1750
					1750 1750 1750 1750 1750 1750 1750 1750 1750 1750 1750 1750 1750 1750 1750 1750 1750
					1750 1750 1750 1750 1750 1750 1750 1750 1750 1750 1750 1750 1750 1750 1750 1750 1750>;
			};

			huawei,cmi {
				huawei,name = "huawei,cmi";
				huawei,report_rate_test = <0>; /* 0:disable test, 1:enable test */

				huawei,highres_upperlimit = <9999 9999 9999>;
				huawei,highres_lowerlimit = <0xD8F1 0xD8F1 0xD8F1>;/* 0xD8F1 == -9999 */

				huawei,rx_cap_upperlimit = <9999>;
				huawei,rx_cap_lowerlimit = <0xD8F1>;

				huawei,tx_cap_upperlimit = <9999>;
				huawei,tx_cap_lowerlimit = <0xD8F1>;

				huawei,deltarawimage_upperlimit = <9999>;
				huawei,deltarawimage_lowerlimit = <0xD8F1>;

				huawei,f51_ctrl_01_low_sensitivity_val = <0x1b>;
				huawei,f51_ctrl_04_low_sensitivity_val = <0x17>;
				huawei,f01_ctrl_05_low_sensitivity_val = <0x05>;
				huawei,f01_ctrl_09_low_sensitivity_val = <0x04>;

				huawei,fullraw_upperlimit =
					<9999 9999 9999 9999 9999 9999 9999 9999 9999 9999 9999 9999 9999 9999 9999 9999 9999 9999 9999 9999 9999 9999 9999 9999 9999 9999 9999 9999
					9999 9999 9999 9999 9999 9999 9999 9999 9999 9999 9999 9999 9999 9999 9999 9999 9999 9999 9999 9999 9999 9999 9999 9999 9999 9999 9999 9999
					9999 9999 9999 9999 9999 9999 9999 9999 9999 9999 9999 9999 9999 9999 9999 9999 9999 9999 9999 9999 9999 9999 9999 9999 9999 9999 9999 9999
					9999 9999 9999 9999 9999 9999 9999 9999 9999 9999 9999 9999 9999 9999 9999 9999 9999 9999 9999 9999 9999 9999 9999 9999 9999 9999 9999 9999
					9999 9999 9999 9999 9999 9999 9999 9999 9999 9999 9999 9999 9999 9999 9999 9999 9999 9999 9999 9999 9999 9999 9999 9999 9999 9999 9999 9999
					9999 9999 9999 9999 9999 9999 9999 9999 9999 9999 9999 9999 9999 9999 9999 9999 9999 9999 9999 9999 9999 9999 9999 9999 9999 9999 9999 9999
					9999 9999 9999 9999 9999 9999 9999 9999 9999 9999 9999 9999 9999 9999 9999 9999 9999 9999 9999 9999 9999 9999 9999 9999 9999 9999 9999 9999
					9999 9999 9999 9999 9999 9999 9999 9999 9999 9999 9999 9999 9999 9999 9999 9999 9999 9999 9999 9999 9999 9999 9999 9999 9999 9999 9999 9999
					9999 9999 9999 9999 9999 9999 9999 9999 9999 9999 9999 9999 9999 9999 9999 9999 9999 9999 9999 9999 9999 9999 9999 9999 9999 9999 9999 9999
					9999 9999 9999 9999 9999 9999 9999 9999 9999 9999 9999 9999 9999 9999 9999 9999 9999 9999 9999 9999 9999 9999 9999 9999 9999 9999 9999 9999
					9999 9999 9999 9999 9999 9999 9999 9999 9999 9999 9999 9999 9999 9999 9999 9999 9999 9999 9999 9999 9999 9999 9999 9999 9999 9999 9999 9999
					9999 9999 9999 9999 9999 9999 9999 9999 9999 9999 9999 9999 9999 9999 9999 9999 9999 9999 9999 9999 9999 9999 9999 9999 9999 9999 9999 9999
					9999 9999 9999 9999 9999 9999 9999 9999 9999 9999 9999 9999 9999 9999 9999 9999 9999 9999 9999 9999 9999 9999 9999 9999 9999 9999 9999 9999
					9999 9999 9999 9999 9999 9999 9999 9999 9999 9999 9999 9999 9999 9999 9999 9999 9999 9999 9999 9999 9999 9999 9999 9999 9999 9999 9999 9999
					9999 9999 9999 9999 9999 9999 9999 9999 9999 9999 9999 9999 9999 9999 9999 9999 9999 9999 9999 9999 9999 9999 9999 9999 9999 9999 9999 9999
					9999 9999 9999 9999 9999 9999 9999 9999 9999 9999 9999 9999 9999 9999 9999 9999 9999 9999 9999 9999 9999 9999 9999 9999 9999 9999 9999 9999>;

				huawei,fullraw_lowerlimit =
					<0 0 0 0 0 0 0 0 0 0 0 0 0 0 0 0 0 0 0 0 0 0 0 0 0 0 0 0
					0 0 0 0 0 0 0 0 0 0 0 0 0 0 0 0 0 0 0 0 0 0 0 0 0 0 0 0
					0 0 0 0 0 0 0 0 0 0 0 0 0 0 0 0 0 0 0 0 0 0 0 0 0 0 0 0
					0 0 0 0 0 0 0 0 0 0 0 0 0 0 0 0 0 0 0 0 0 0 0 0 0 0 0 0
					0 0 0 0 0 0 0 0 0 0 0 0 0 0 0 0 0 0 0 0 0 0 0 0 0 0 0 0
					0 0 0 0 0 0 0 0 0 0 0 0 0 0 0 0 0 0 0 0 0 0 0 0 0 0 0 0
					0 0 0 0 0 0 0 0 0 0 0 0 0 0 0 0 0 0 0 0 0 0 0 0 0 0 0 0
					0 0 0 0 0 0 0 0 0 0 0 0 0 0 0 0 0 0 0 0 0 0 0 0 0 0 0 0
					0 0 0 0 0 0 0 0 0 0 0 0 0 0 0 0 0 0 0 0 0 0 0 0 0 0 0 0
					0 0 0 0 0 0 0 0 0 0 0 0 0 0 0 0 0 0 0 0 0 0 0 0 0 0 0 0
					0 0 0 0 0 0 0 0 0 0 0 0 0 0 0 0 0 0 0 0 0 0 0 0 0 0 0 0
					0 0 0 0 0 0 0 0 0 0 0 0 0 0 0 0 0 0 0 0 0 0 0 0 0 0 0 0
					0 0 0 0 0 0 0 0 0 0 0 0 0 0 0 0 0 0 0 0 0 0 0 0 0 0 0 0
					0 0 0 0 0 0 0 0 0 0 0 0 0 0 0 0 0 0 0 0 0 0 0 0 0 0 0 0
					0 0 0 0 0 0 0 0 0 0 0 0 0 0 0 0 0 0 0 0 0 0 0 0 0 0 0 0
					0 0 0 0 0 0 0 0 0 0 0 0 0 0 0 0 0 0 0 0 0 0 0 0 0 0 0 0>;
			};
		};
	};

	/*To disable gen-vkeys.c probe,avoid generate kobject*/
	gen-vkeys {
		compatible = "huawei,gen-vkeys";
		label = "synaptics_rmi4_i2c";
		qcom,disp-maxx = <720>;
		qcom,disp-maxy = <1280>;
		qcom,panel-maxx = <720>;
		qcom,panel-maxy = <1369>;
		qcom,key-codes = <158 172 139>;
	};

};

